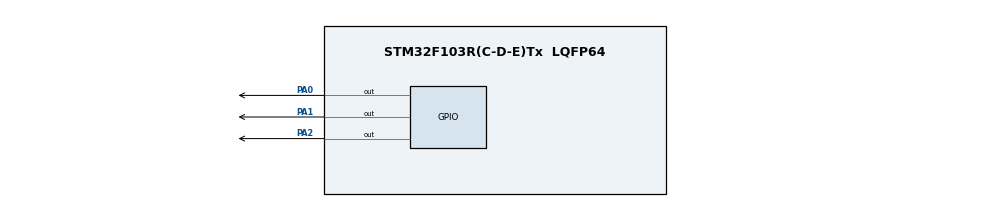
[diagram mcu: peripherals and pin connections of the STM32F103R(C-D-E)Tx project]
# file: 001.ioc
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Mcu.Family=STM32F1
Mcu.Name=STM32F103R(C-D-E)Tx
Mcu.Package=LQFP64
NVIC.PriorityGroup=NVIC_PRIORITYGROUP_4
NVIC.TIM6_IRQn=true\:0\:0\:false\:false\:true
PA0-WKUP.Signal=GPIO_Output
PA1.Signal=GPIO_Output
PA13.Mode=Serial_Wire
PA13.Signal=SYS_JTMS-SWDIO
PA14.Mode=Serial_Wire
PA14.Signal=SYS_JTCK-SWCLK
PA2.Signal=GPIO_Output
ProjectManager.HeapSize=0x200
ProjectManager.StackSize=0x400
ProjectManager.TargetToolchain=SW4STM32
RCC.APB1Freq_Value=8000000
RCC.APB2Freq_Value=8000000
TIM6.Prescaler=47999
VP_TIM6_VS_ClockSourceINT.Mode=Enable_Timer
board=001

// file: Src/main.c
/**
  ******************************************************************************
  * File Name          : main.c
  * Description        : Main program body
  ******************************************************************************
  *
  * COPYRIGHT(c) 2016 STMicroelectronics
  *
  * Redistribution and use in source and binary forms, with or without modification,
  * are permitted provided that the following conditions are met:
  *   1. Redistributions of source code must retain the above copyright notice,
  *      this list of conditions and the following disclaimer.
  *   2. Redistributions in binary form must reproduce the above copyright notice,
  *      this list of conditions and the following disclaimer in the documentation
  *      and/or other materials provided with the distribution.
  *   3. Neither the name of STMicroelectronics nor the names of its contributors
  *      may be used to endorse or promote products derived from this software
  *      without specific prior written permission.
  *
  * THIS SOFTWARE IS PROVIDED BY THE COPYRIGHT HOLDERS AND CONTRIBUTORS "AS IS"
  * AND ANY EXPRESS OR IMPLIED WARRANTIES, INCLUDING, BUT NOT LIMITED TO, THE
  * IMPLIED WARRANTIES OF MERCHANTABILITY AND FITNESS FOR A PARTICULAR PURPOSE ARE
  * DISCLAIMED. IN NO EVENT SHALL THE COPYRIGHT HOLDER OR CONTRIBUTORS BE LIABLE
  * FOR ANY DIRECT, INDIRECT, INCIDENTAL, SPECIAL, EXEMPLARY, OR CONSEQUENTIAL
  * DAMAGES (INCLUDING, BUT NOT LIMITED TO, PROCUREMENT OF SUBSTITUTE GOODS OR
  * SERVICES; LOSS OF USE, DATA, OR PROFITS; OR BUSINESS INTERRUPTION) HOWEVER
  * CAUSED AND ON ANY THEORY OF LIABILITY, WHETHER IN CONTRACT, STRICT LIABILITY,
  * OR TORT (INCLUDING NEGLIGENCE OR OTHERWISE) ARISING IN ANY WAY OUT OF THE USE
  * OF THIS SOFTWARE, EVEN IF ADVISED OF THE POSSIBILITY OF SUCH DAMAGE.
  *
  ******************************************************************************
  */
#include "stm32f1xx_hal.h"

TIM_HandleTypeDef htim6;

/* USER CODE BEGIN PV */
/* Private variables ---------------------------------------------------------*/
uint16_t delay;

/* USER CODE END PV */

void SystemClock_Config(void);
static void MX_GPIO_Init(void);
static void MX_TIM6_Init(void);

/* USER CODE BEGIN PFP */
/* Private function prototypes -----------------------------------------------*/

/* USER CODE END PFP */

int main(void)
{

  /* MCU Configuration----------------------------------------------------------*/

  /* Reset of all peripherals, Initializes the Flash interface and the Systick. */
  HAL_Init();

  /* Configure the system clock */
  SystemClock_Config();

  /* Initialize all configured peripherals */
  MX_GPIO_Init();
  MX_TIM6_Init();
    HAL_TIM_Base_Start_IT(&htim6);
  /* USER CODE BEGIN 2 */
    HAL_GPIO_WritePin(GPIOA,GPIO_PIN_0, RESET);
    HAL_GPIO_WritePin(GPIOA,GPIO_PIN_1, RESET);
    HAL_GPIO_WritePin(GPIOA,GPIO_PIN_2, RESET);
  /* USER CODE END 2 */

  /* Infinite loop */
  /* USER CODE BEGIN WHILE */
  while (1)
  {

    for (delay=0; delay < 50000; delay++);
    HAL_GPIO_TogglePin(GPIOA,GPIO_PIN_1);

  /* USER CODE END WHILE */

  }

}

/** System Clock Configuration
*/
void SystemClock_Config(void)
{

  RCC_OscInitTypeDef RCC_OscInitStruct;
  RCC_ClkInitTypeDef RCC_ClkInitStruct;

  RCC_OscInitStruct.OscillatorType = RCC_OSCILLATORTYPE_HSI;
  RCC_OscInitStruct.HSIState = RCC_HSI_ON;
  RCC_OscInitStruct.HSICalibrationValue = 16;
  RCC_OscInitStruct.PLL.PLLState = RCC_PLL_NONE;
  HAL_RCC_OscConfig(&RCC_OscInitStruct);

  RCC_ClkInitStruct.ClockType = RCC_CLOCKTYPE_HCLK|RCC_CLOCKTYPE_SYSCLK
                              |RCC_CLOCKTYPE_PCLK1|RCC_CLOCKTYPE_PCLK2;
  RCC_ClkInitStruct.SYSCLKSource = RCC_SYSCLKSOURCE_HSI;
  RCC_ClkInitStruct.AHBCLKDivider = RCC_SYSCLK_DIV1;
  RCC_ClkInitStruct.APB1CLKDivider = RCC_HCLK_DIV1;
  RCC_ClkInitStruct.APB2CLKDivider = RCC_HCLK_DIV1;
  HAL_RCC_ClockConfig(&RCC_ClkInitStruct, FLASH_LATENCY_0);

  HAL_SYSTICK_Config(HAL_RCC_GetHCLKFreq()/1000);

  HAL_SYSTICK_CLKSourceConfig(SYSTICK_CLKSOURCE_HCLK);

  /* SysTick_IRQn interrupt configuration */
  HAL_NVIC_SetPriority(SysTick_IRQn, 0, 0);
}

/* TIM6 init function */
void MX_TIM6_Init(void)
{

  TIM_MasterConfigTypeDef sMasterConfig;

  htim6.Instance = TIM6;
  htim6.Init.Prescaler = 49;
  htim6.Init.CounterMode = TIM_COUNTERMODE_UP;
  htim6.Init.Period = 1024;
  HAL_TIM_Base_Init(&htim6);

  sMasterConfig.MasterOutputTrigger = TIM_TRGO_RESET;
  sMasterConfig.MasterSlaveMode = TIM_MASTERSLAVEMODE_DISABLE;
  HAL_TIMEx_MasterConfigSynchronization(&htim6, &sMasterConfig);

}

/** Configure pins as
        * Analog
        * Input
        * Output
        * EVENT_OUT
        * EXTI
*/
void MX_GPIO_Init(void)
{

  GPIO_InitTypeDef GPIO_InitStruct;

  /* GPIO Ports Clock Enable */
  __HAL_RCC_GPIOA_CLK_ENABLE();

  /*Configure GPIO pin Output Level */
  HAL_GPIO_WritePin(GPIOA, GPIO_PIN_0|GPIO_PIN_1|GPIO_PIN_2, GPIO_PIN_RESET);

  /*Configure GPIO pins : PA0 PA1 PA2 */
  GPIO_InitStruct.Pin = GPIO_PIN_0|GPIO_PIN_1|GPIO_PIN_2;
  GPIO_InitStruct.Mode = GPIO_MODE_OUTPUT_PP;
  GPIO_InitStruct.Speed = GPIO_SPEED_FREQ_LOW;
  HAL_GPIO_Init(GPIOA, &GPIO_InitStruct);

}

/************************ (C) COPYRIGHT STMicroelectronics *****END OF FILE****/
